# SIM3C166_B register map
File version: 1
CPU: 
Registers are 32-bit, read-write, reset 0x0 unless marked. A register's access mark holds for its fields unless they carry their own. Offsets are from the block's base; [hi:lo] are bit positions; {n}, {i} and the like mark numbered series.

## DMACTRL_0
Base 0x40036000
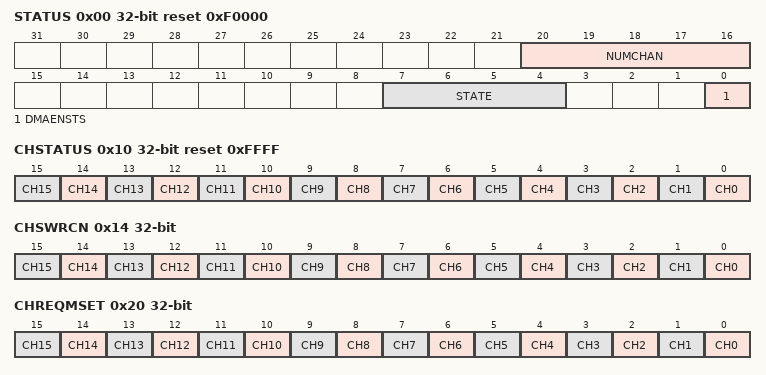
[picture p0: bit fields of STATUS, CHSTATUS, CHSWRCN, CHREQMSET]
0x00 STATUS reset 0xF0000 — Controller Status
  [20:16] NUMCHAN ro — Number of Supported DMA Channels.
  [7:4] STATE ro — State Machine State.
    0=IDLE; 1=READING_CHANNEL_CONFIG (Reading channel controller data.); 2=READING_SOURCE_POINTER (Reading source data end pointer.); 3=READING_DEST_POINTER (Reading destination data end pointer.); 4=READING_SOURCE_DATA; 5=WRITING_DEST_DATA (Writing destination data.); 6=WAITING_DMA_REQ_CLEAR (Waiting for a DMA request to clear.); 7=WRITING_CHANNEL_CONFIG (Writing channel controller data.); 8=STALLED; 9=DONE; 10=SCATTER_GATHER_TRANSITION (Peripheral scatter-gather transition.)
  [0] DMAENSTS ro — DMA Enable Status.
    0=NOT_SET (DMA controller is disabled); 1=SET (DMA controller is enabled.)
0x04 CONFIG — Controller Configuration
  [0] DMAEN wo — DMA Enable.
    0=DISABLED (Disable the DMA controller.); 1=ENABLED (Enable the DMA controller.)
0x08 BASEPTR — Base Pointer
  [31:5] BASEPTR — Control Base Pointer.
0x0C ABASEPTR reset 0x100 — Alternate Base Pointer
  [31:0] ABASEPTR ro — Alternate Control Base Pointer.
0x10 CHSTATUS reset 0xFFFF — Channel Status
  [n] CH{n} ro (n=0..15) — Channel {n} Status.
    0=NOT_WAITING (DMA Channel {n} is not waiting for a data request.); 1=WAITING (DMA Channel {n} is waiting for a data request.)
0x14 CHSWRCN — Channel Software Request Control
  [n] CH{n} wo (n=0..15) — Channel {n} Software Request.
    0=DO_NOT_GENERATE_SW_REQ (DMA Channel {n} does not generate a software data request.); 1=GENERATE_SW_REQ (DMA Channel {n} generates a software data request.)
0x20 CHREQMSET — Channel Request Mask Set
  [n] CH{n} (n=0..15) — Channel {n} Request Mask Enable.
    1=ENABLED (Read: 0: DMA Channel {n} peripheral data requests enabled. 1: DMA Channel {n} peripheral data requests disabled. Write: 0: No effect (use CHREQMCLR to clear). 1: Disable DMA Channel {n} peripheral data requests.)
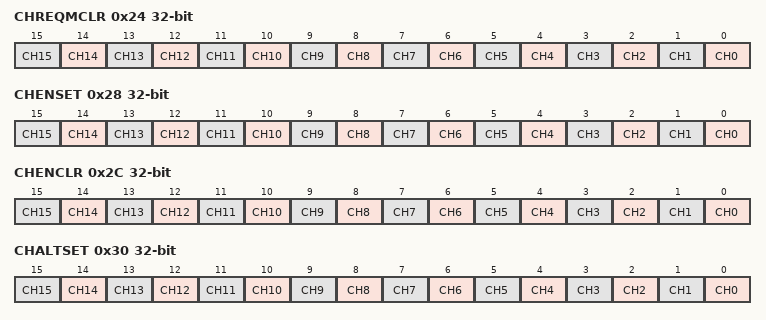
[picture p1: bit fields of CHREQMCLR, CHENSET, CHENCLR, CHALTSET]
0x24 CHREQMCLR — Channel Request Mask Clear
  [n] CH{n} wo (n=0..15) — Channel {n} Request Mask Disable.
    0=RESERVED (No effect.); 1=DISABLED (Enable DMA Channel {n} peripheral data requests.)
0x28 CHENSET — Channel Enable Set
  [n] CH{n} (n=0..15) — Channel {n} Enable.
    1=ENABLED (Read: 0: DMA Channel {n} disabled. 1: DMA Channel {n} enabled. Write: 0: No effect (use CHENCLR to clear). 1: Enable DMA Channel {n}.)
0x2C CHENCLR — Channel Enable Clear
  [n] CH{n} wo (n=0..15) — Channel {n} Disable.
    0=RESERVED (No effect.); 1=DISABLED (Disable DMA Channel {n}.)
0x30 CHALTSET — Channel Alternate Select Set
  [n] CH{n} (n=0..15) — Channel {n} Alternate Enable.
    1=ENABLED (Read: 0: DMA Channel {n} is using primary data structure. 1: DMA Channel {n} is using alternate data structure. Write: 0: No effect (use CHALTCLR to clear). 1: Use the alternate data structure for DMA Channel {n}.)
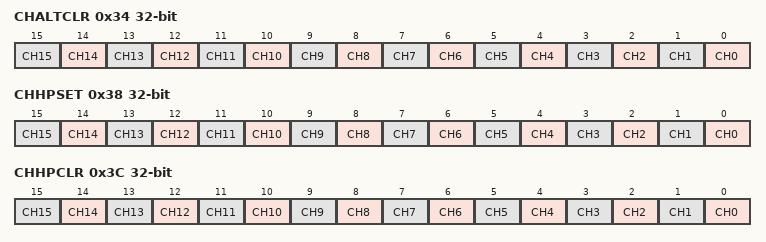
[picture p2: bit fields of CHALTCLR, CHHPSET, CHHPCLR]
0x34 CHALTCLR — Channel Alternate Select Clear
  [n] CH{n} wo (n=0..15) — Channel {n} Alternate Disable.
    0=RESERVED (No effect.); 1=DISABLED (Use the primary data structure for DMA Channel {n}.)
0x38 CHHPSET — Channel High Priority Set
  [n] CH{n} (n=0..15) — Channel {n} High Priority Enable.
    1=ENABLED (Read: 0: DMA Channel {n} is using the default priority level. 1: DMA Channel {n} is using the high priority level. Write: 0: No effect (use CHHPCLR to clear). 1: Use the high priority level for DMA Channel {n}.)
0x3C CHHPCLR — Channel High Priority Clear
  [n] CH{n} wo (n=0..15) — Channel {n} High Priority Disable.
    0=RESERVED (No effect.); 1=DISABLED (Use the high default level for DMA Channel {n}.)
0x4C BERRCLR — Bus Error Clear
  [0] ERROR — DMA Bus Error Clear.
    1=CLEAR (Read: 0: DMA error did not occur. 1: DMA error occurred since the last time ERROR was cleared. Write: 0: No effect. 1: Clear the DMA error flag.)
